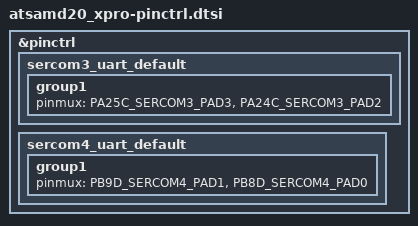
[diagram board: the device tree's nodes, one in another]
/*
 * Copyright (c) 2022, Gerson Fernando Budke <nandojve@gmail.com>
 * SPDX-License-Identifier: Apache-2.0
 */

#include <dt-bindings/pinctrl/samd20jXab-pinctrl.h>

&pinctrl {
	sercom3_uart_default: sercom3_uart_default {
		group1 {
			pinmux = <PA25C_SERCOM3_PAD3>,
				 <PA24C_SERCOM3_PAD2>;
		};
	};
	sercom4_uart_default: sercom4_uart_default {
		group1 {
			pinmux = <PB9D_SERCOM4_PAD1>,
				 <PB8D_SERCOM4_PAD0>;
		};
	};
};
